# QN908XC register map
Vendor: nxp.com; File version: 1.0
CPU: CM4 r0p1, little endian, no MPU, no FPU, 0x3 interrupt priority bits, 0x0 interrupts
Registers are 32-bit, read-write, reset 0x0 unless marked. A register's access mark holds for its fields unless they carry their own. Offsets are from the block's base; [hi:lo] are bit positions; {n}, {i} and the like mark numbered series.

## FLASH
Base 0x40081000
0x00 INI_RD_EN — flash initial read register
  [0] INI_RD_EN — enable contoller to automatically read GDR repaired information and lock bit
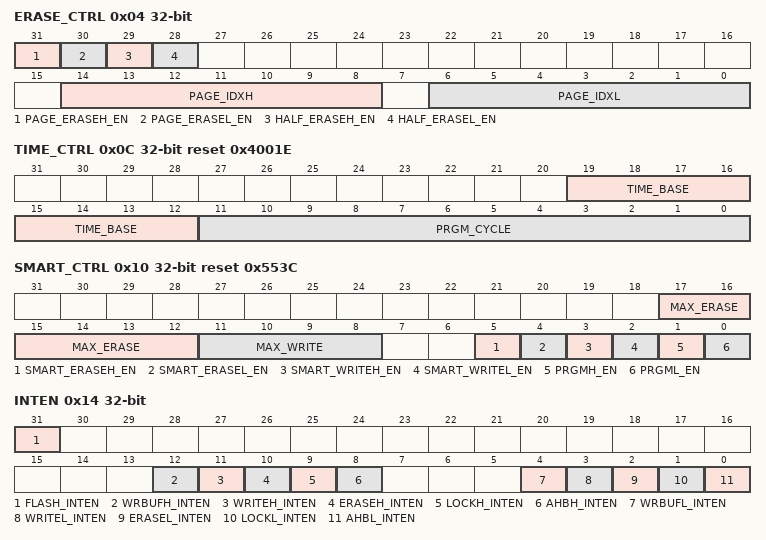
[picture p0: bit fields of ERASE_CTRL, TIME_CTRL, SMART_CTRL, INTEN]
0x04 ERASE_CTRL — flash erase control register
  [31] PAGE_ERASEH_EN — High 256KB block page erase enable. This bit initiates a page erase operation when set. This bit is set by software and reset at the end of page erase operation by hardware.
  [30] PAGE_ERASEL_EN — Low 256KB block page erase enable. This bit initiates a page erase operation when set. This bit is set by software and reset at the end of page erase operation by hardware.
  [29] HALF_ERASEH_EN — Write '1' to Enable Mass Erase High 256KB Flash; Write '0' is inactive. This bit is set by software and reset at the end of high 256KB flash mass erase operation by hardware.
  [28] HALF_ERASEL_EN — Write '1' to Enable Mass Erase Low 256KB Flash; Write '0' is inactive. This bit is set by software and reset at the end of low 256KB flash mass erase operation by hardware.
  [14:8] PAGE_IDXH — High 256KB page erase index
  [6:0] PAGE_IDXL — Low 256KB page erase index
0x08 ERASE_TIME reset 0x9C400 — flash erase time setting register
  [19:0] ERASE_TIME_BASE — Erase time, which is used to control Terase, Tme and Tsme. An 8MHz clock is to count the erase time. The maximum time of erase is 100ms. Default value is 640000 cycles in 8 MHz, that's 80 ms. User should set a pessimistic value to avoid possible error in erase operation.
0x0C TIME_CTRL reset 0x4001E — flash operation time setting register
  [19:12] TIME_BASE — Max write operation times in one program, which are used to control Terase and Tme. User should set a pessimistic value to avoid possible error in erase/page erase operation. When user do write operation: It is used to limit allowed write numbers. (Max 21 ms-Tnvs-Tpgs-Tpgh-Tnvh)/18us = 1167 This register is only used when common write.
  [11:0] PRGM_CYCLE — Time base of some flash timing parameters, which represents 2 us. Default value is 64 cycles in 32 MHz (ahb clock). It is used in write and erase operations.
0x10 SMART_CTRL reset 0x553C — smart erase control register
  [17:12] MAX_ERASE — When smart erase is used, this is the maximum retry number for one erase operation.
  [11:8] MAX_WRITE — When smart program is used, this is the maximum retry number for one write operation.
  [5] SMART_ERASEH_EN — It enable High 256KB Flash Smart erase flow; When smart erase is done, hardware automatically clear it
  [4] SMART_ERASEL_EN — It enable Low 256KB Flash Smart erase flow; When smart erase is done, hardware automatically clear it
  [3] SMART_WRITEH_EN — It enable High 256KB Flash Smart program flow. When smart write is done, hardware automatically clear it
  [2] SMART_WRITEL_EN — It enable Low 256KB Flash Smart program flow. When smart write is done, hardware automatically clear it
  [1] PRGMH_EN — It enable High 256KB Flash write operation;
  [0] PRGML_EN — It enable Low 256KB Flash write operation;
0x14 INTEN (reset mask 0x80000007) — interrupt enable register
  [31] FLASH_INTEN — flash total interrupt enable
  [12] WRBUFH_INTEN — high 256K flash write buffer status interrupt enable
  [11] WRITEH_INTEN — high 256K flash write status interrupt enable
  [10] ERASEH_INTEN — high 256K flash erase status interrupt enable
  [9] LOCKH_INTEN — high 256K flash lock error interrupt enable
  [8] AHBH_INTEN — high 256K flash AHB error interrupt enable
  [4] WRBUFL_INTEN — low 256K flash write buffer status interrupt enable
  [3] WRITEL_INTEN — low 256K flash write status interrupt enable
  [2] ERASEL_INTEN — low 256K flash erase status interrupt enable
  [1] LOCKL_INTEN — low 256K flash lock error interrupt enable
  [0] AHBL_INTEN — low 256K flash AHB error interrupt enable
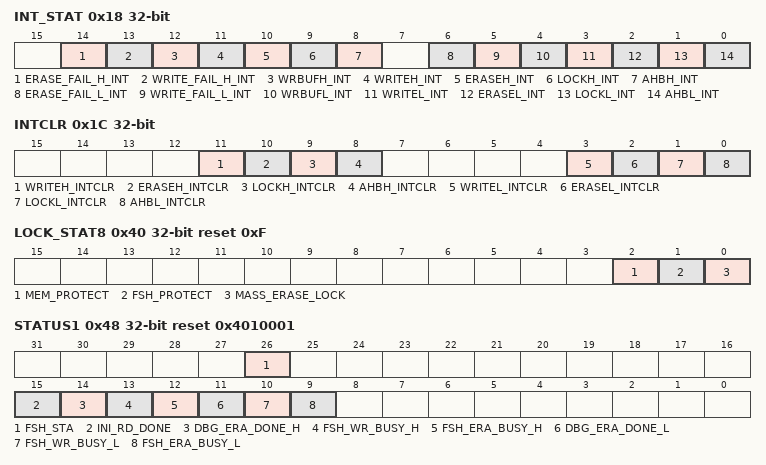
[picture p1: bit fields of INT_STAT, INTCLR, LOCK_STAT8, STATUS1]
0x18 INT_STAT — interrupt status register
  [14] ERASE_FAIL_H_INT — When smart erase of high 256KB Flash is enable, 0 = Smart erase is successful, 1 = Smart erase is fail.
  [13] WRITE_FAIL_H_INT — When smart write of high 256KB Flash is enable, 0 = Smart write is successful, 1 = Smart write is fail.
  [12] WRBUFH_INT — it is high 256KB Flash Write Buffer empty interrupt status 0 = write buffer is not empty 1 = write buffer is empty It is auto cleared when write buffer is written. It is enabled only when PRGMH_EN is enabled and write buffer is empty
  [11] WRITEH_INT — it is high 256KB Flash write operation done interrupt status If write is used, it indicates one program is done.
  [10] ERASEH_INT — it is high 256KB Flash Erase operation done interrupt status If erase is used, it indicates one erase is done.
  [9] LOCKH_INT — it is high 256KB Flash Lock page be accessed interrupt status
  [8] AHBH_INT — it is high 256KB Flash AHB error interrupt stat 1 indicates AHB operation error AHB error include: Write/read unmapped space; AHB align rules violation; Byte/half-word Flash write operation;
  [6] ERASE_FAIL_L_INT — When smart erase of low 256KB Flash is enable, 0 = Smart erase is successful, 1 = Smart erase is fail.
  [5] WRITE_FAIL_L_INT — When smart write of low 256KB Flash is enable, 0 = Smart write is successful, 1 = Smart write is fail.
  [4] WRBUFL_INT — It is low 256KB Write Buffer empty interrupt status 0 = write buffer is not empty 1 = write buffer is empty It is auto cleared when write buffer is written. It is enabled only when PRGML_EN is enabled and write buffer is empty
  [3] WRITEL_INT — It is low 256KB write operation done interrupt status If write is used, it indicates one program is done.
  [2] ERASEL_INT — It is low 256KB Erase operation done interrupt status If erase is used, it indicates one erase is done.
  [1] LOCKL_INT — It is low 256KB Flash Lock page be accessed interrupt status
  [0] AHBL_INT — It is low 256KB Flash AHB error interrupt stat. 1 indicates AHB operation error AHB error include: Write/read unmapped space; AHB align rules violation; Byte/half-word Flash write operation;
0x1C INTCLR — interrupt clear register
  [11] WRITEH_INTCLR write-1-clears — high 256K flash write status interrupt clear
  [10] ERASEH_INTCLR write-1-clears — high 256K flash erase status interrupt clear
  [9] LOCKH_INTCLR write-1-clears — high 256K flash lock error interrupt clear
  [8] AHBH_INTCLR write-1-clears — high 256K flash AHB error interrupt clear
  [3] WRITEL_INTCLR write-1-clears — low 256K flash write status interrupt clear
  [2] ERASEL_INTCLR write-1-clears — low 256K flash erase status interrupt clear
  [1] LOCKL_INTCLR write-1-clears — low 256K flash lock error interrupt clear
  [0] AHBL_INTCLR write-1-clears — low 256K flash AHB error interrupt clear
0x20 LOCK_STAT0 ro reset 0xFFFFFFFF — lock control register 0
  [31:0] PAGE_LOCK0 — Low 256K flash main memory page 0-31 write and erase lock status
{0x20+4i} LOCK_STAT{i} ro reset 0xFFFFFFFF (i=1..3)
  [31:0] PAGE_LOCK{i} — Low 256K flash main memory page {32i}-{32i+31} write and erase lock status
{0x20+4i} LOCK_STAT{i} ro reset 0xFFFFFFFF (i=4..7)
  [31:0] PAGE_LOCK{i} — high 256K flash main memory page {32i-128}-{32i-97} write and erase lock status
0x40 LOCK_STAT8 reset 0xF
  [2] MEM_PROTECT — SWD memory protection status 0 : Memory is unprotected 1 : Memory is protected
  [1] FSH_PROTECT — SWD flash protection status 0 : flash is unprotected 1 : flash is protected
  [0] MASS_ERASE_LOCK — Mass erase operation lock status 0 : Mass erase operation is locked 1 : Mass erase operation is unlocked
0x48 STATUS1 ro reset 0x4010001
  [26] FSH_STA — when 0 means data information is 0x55AA.
  [15] INI_RD_DONE — flash initial read done.
  [14] DBG_ERA_DONE_H — A flash block 1 debug initiated smart mass erase status. 0 : no debug port initiated flash block 1 smart mass erase operation in progress. 1 : debug port initiated flash block 1 smart mass erase operation in progress.
  [13] FSH_WR_BUSY_H — flash block 1 write operation status: 0 : no flash block 1 write operation in progress. 1 : flash block 1 write operation is in progress.
  [12] FSH_ERA_BUSY_H — flash block 1 erase operation status 0 : no flash block 1 erase operation in progress. 1 : flash block 1 erase operation is in progress.
  [11] DBG_ERA_DONE_L — A flash block 0 debug initiated smart mass erase status. 0 : no debug port initiated flash block 0 smart mass erase operation in progress. 1 : debug port initiated flash block 0 smart mass erase operation in progress.
  [10] FSH_WR_BUSY_L — flash block 0 write operation status: 0 : no flash block 0 write operation in progress. 1 : flash block 0 write operation is in progress.
  [9] FSH_ERA_BUSY_L — flash block 0 erase operation status 0 : no flash block 0 erase operation in progress. 1 : flash block 0 erase operation is in progress.
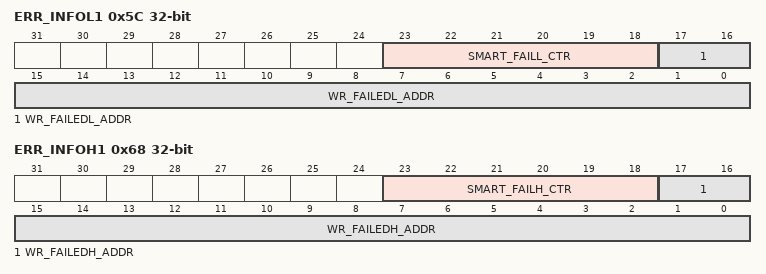
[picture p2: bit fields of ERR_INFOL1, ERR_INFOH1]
0x5C ERR_INFOL1 ro
  [23:18] SMART_FAILL_CTR — The amount of fails during a smart write or smart erase is stored in this bit field
  [17:0] WR_FAILEDL_ADDR — When a flash block 0 smart write fails, the address is stored in this bit filed
0x60 ERR_INFOL2 ro
  [31:0] WR_FAILEDL_DATA — When a flash block 0 smart write fails, the data is stored in this bit field
0x64 ERR_INFOL3 ro
  [17:0] ERA_FAILEDL_INFO — When a smart erase on flash block 0 fails, the address is stored in this bit field
0x68 ERR_INFOH1 ro
  [23:18] SMART_FAILH_CTR — The amount of fails during a msart write or smart erase is stored int his bit field
  [17:0] WR_FAILEDH_ADDR — When a flash block 1 smart write fails, the address is stored in this bit field
0x6C ERR_INFOH2 ro
  [31:0] WR_FAILEDH_DATA — When a flash block 1 smart write fails, the data is stored in this bit field
0x70 ERR_INFOH3 ro
  [17:0] ERA_FAILEDH_INFO — when a smart erase on flash block 1 fails, the address is stored in this bit field
0xA8 DEBUG_PASSWORD
  [31:0] DEBUG_PASSWORD — An SWD initiated smart mass erase operation will only be issued if this register is programmed with the value 0xCA1E093F.
0xAC ERASE_PASSWORD
  [31:0] ERASE_PASSWORD — When this register is programmed with the value 0xCA1E093F, a FW initiated mass erase or page erase operation will bypass the current lock and protection scheme.
